AUTOSAR XML (schema 00046)
package /Runnable_lab2
  sender reciever interface SRI_Output
    data Sum_Result: type=uint32
  sender reciever interface SRI_Inputs
    data var1: type=uint16
    data var2: type=uint16
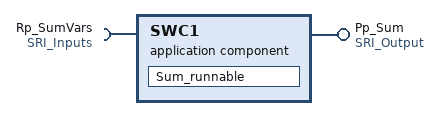
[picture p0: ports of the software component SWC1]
  application sw component type SWC1
    provide port Pp_Sum: provided-interface=SRI_Output
    require port Rp_SumVars: required-interface=SRI_Inputs
    behavior SWC1_behav
      runnable Sum_runnable: symbol=Sum
        data-write-access:
          access var1_data: accessed-variable=Rp_SumVars.var1
          access var2_data: accessed-variable=Rp_SumVars.var2
          access Sum_Result_data: accessed-variable=Pp_Sum.Sum_Result
